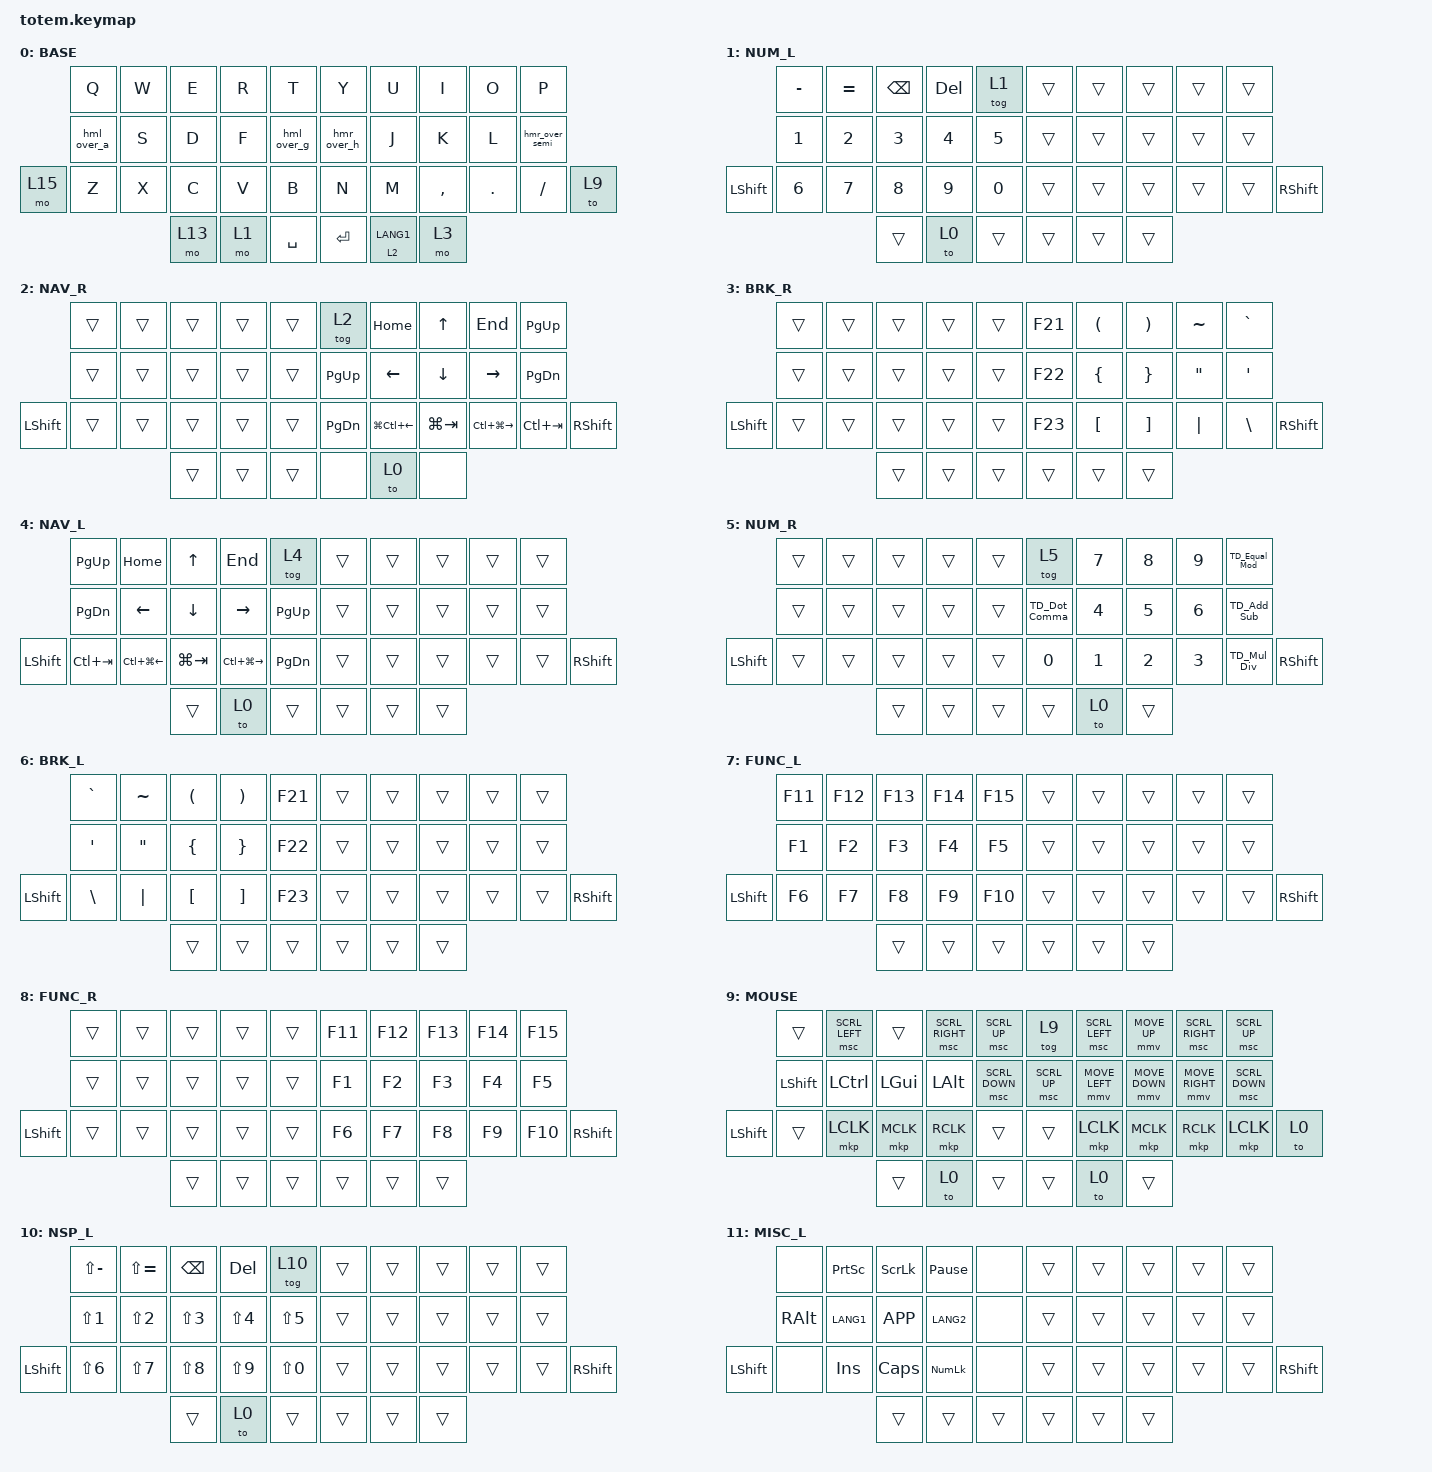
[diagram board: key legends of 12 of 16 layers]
//
//                                                        ▀▀▀▀▀     ▀▀▀▀▀          ▀▀█▀▀
//                                                        ▄▀▀▀▄  ▄  ▄▀▀▀▄  ▄  ▄▀▀▀▄  █  ▄▀▀▀▄
//                                                        █   █  █  █   █  █  █   █  █  █   █
//                                                         ▀▀▀   █   ▀▀▀   █   ▀▀▀   ▀   ▀▀▀
//                                                               █      ▄▄▄█▄▄▄    █   █  
//                                                               ▀      █  █  █     █▄█
//                                                             ▀▀▀▀▀    █  █  █      ▀
//                                                                      ▀  ▀  ▀
//
// ▄▄▄▄▄▄▄▄▄▄▄▄▄▄▄▄▄▄▄▄▄▄▄▄▄▄▄▄▄▄▄▄▄▄▄▄▄▄▄▄▄▄▄▄▄▄▄▄▄▄▄▄▄▄▄▄▄▄▄▄▄▄▄▄▄▄▄▄▄▄▄▄▄▄▄▄▄▄▄▄▄▄▄▄▄▄▄▄▄▄▄▄▄▄▄▄▄▄▄▄▄▄▄▄▄▄▄▄▄▄▄▄▄▄▄▄▄▄▄▄▄▄▄▄▄▄▄▄▄▄▄▄▄▄▄▄▄▄▄▄▄▄▄▄▄▄▄▄▄

#include <behaviors.dtsi>
#include <dt-bindings/zmk/bt.h>
#include <dt-bindings/zmk/keys.h>
#include <dt-bindings/zmk/outputs.h>
#include <dt-bindings/zmk/pointing.h>

&mt {
    quick-tap-ms = <175>;
    flavor = "balanced";
};

&lt {
    tapping-term-ms = <180>;
    flavor = "hold-preferred";
    hold-while-undecided;
};

&tog { toggle-mode = "on"; };

/ {
    combos {
        compatible = "zmk,combos";

        CAPS_L {
            bindings = <&kp CAPS>;
            key-positions = <23 33>;
            timeout-ms = <30>;
            layers = <0>;
        };

        TAB_L {
            bindings = <&kp TAB>;
            key-positions = <14 34>;
            timeout-ms = <30>;
            layers = <0>;
        };

        ENTER_L {
            bindings = <&kp ENTER>;
            key-positions = <34 4>;
            timeout-ms = <30>;
            layers = <0>;
        };

        ESC_L {
            bindings = <&kp ESC>;
            key-positions = <33 1>;
            timeout-ms = <30>;
            layers = <0>;
        };

        VOL_UP_L {
            bindings = <&kp C_VOL_UP>;
            key-positions = <33 4>;
            timeout-ms = <30>;
            require-prior-idle-ms = <200>;
            layers = <0>;
        };

        VOL_DN_L {
            bindings = <&kp C_VOL_DN>;
            key-positions = <33 14>;
            timeout-ms = <30>;
            require-prior-idle-ms = <200>;
            layers = <0>;
        };

        LCTRL_L {
            bindings = <&kp LCTRL>;
            key-positions = <11 12>;
            timeout-ms = <30>;
            require-prior-idle-ms = <70>;
            slow-release;
            layers = <0>;
        };

        LGUI_L {
            bindings = <&kp LGUI>;
            key-positions = <12 13>;
            timeout-ms = <30>;
            require-prior-idle-ms = <70>;
            slow-release;
            layers = <0>;
        };

        LALT_L {
            bindings = <&kp LALT>;
            key-positions = <13 14>;
            timeout-ms = <30>;
            require-prior-idle-ms = <70>;
            slow-release;
            layers = <0>;
        };

        MO_FUNC_L {
            bindings = <&mo 7>;
            key-positions = <33 13>;
            timeout-ms = <30>;
            slow-release;
            layers = <0 2 3 5 8 12>;
        };

        MO_FUNC_R {
            bindings = <&mo 8>;
            key-positions = <36 16>;
            timeout-ms = <30>;
            slow-release;
            layers = <0 1 4 6 7 10 11>;
        };

        MO_NAV_L {
            bindings = <&mo 4>;
            key-positions = <33 12>;
            timeout-ms = <30>;
            slow-release;
            layers = <0 2 3 5 8 12>;
        };

        MO_NUM_R {
            bindings = <&mo 5>;
            key-positions = <17 36>;
            timeout-ms = <30>;
            slow-release;
            layers = <0 1 4 6 7 10 11>;
        };

        MO_MISC_L {
            bindings = <&mo 11>;
            key-positions = <11 33>;
            timeout-ms = <30>;
            slow-release;
            layers = <0 2 3 5 8 12>;
        };

        MO_MISC_R {
            bindings = <&mo 12>;
            key-positions = <36 18>;
            timeout-ms = <30>;
            slow-release;
            layers = <0 1 4 6 7 10 11>;
        };

        MO_BRK_L {
            bindings = <&mo 6>;
            key-positions = <33 25>;
            timeout-ms = <30>;
            slow-release;
            layers = <0 2 3 5 8 12>;
        };

        MO_NUMSP_L {
            bindings = <&mo 10>;
            key-positions = <33 24>;
            timeout-ms = <30>;
            slow-release;
            layers = <0 2 3 5 8 12>;
        };

        MO_MOUSE {
            bindings = <&mo 9>;
            key-positions = <36 27>;
            timeout-ms = <30>;
            require-prior-idle-ms = <200>;
            slow-release;
            layers = <0>;
        };

        TO_BASE_L {
            bindings = <&to 0>;
            key-positions = <32 33 34>;
            timeout-ms = <30>;
        };

        MO_SETTING {
            bindings = <&mo 14>;
            key-positions = <11 4 2 33>;
            timeout-ms = <30>;
            slow-release;
        };

        bootload {
            bindings = <&bootloader>;
            key-positions = <4 25>;
            layers = <14>;
        };

        sysreset {
            bindings = <&sys_reset>;
            key-positions = <11 3>;
            layers = <14>;
        };

        LCTRL_SHFT_L {
            bindings = <&kp LC(LSHIFT)>;
            key-positions = <10 11>;
            timeout-ms = <30>;
            require-prior-idle-ms = <70>;
            slow-release;
            layers = <0>;
        };

        LALT_SHFT_L {
            bindings = <&kp LA(LSHIFT)>;
            key-positions = <10 13>;
            timeout-ms = <30>;
            require-prior-idle-ms = <70>;
            slow-release;
            layers = <0>;
        };

        LCTRL_ALT_L {
            bindings = <&kp LC(LALT)>;
            key-positions = <11 14>;
            timeout-ms = <30>;
            require-prior-idle-ms = <70>;
            slow-release;
            layers = <0>;
        };

        LGUI_SHFT_L {
            bindings = <&kp LS(LGUI)>;
            key-positions = <10 12>;
            timeout-ms = <30>;
            require-prior-idle-ms = <70>;
            slow-release;
            layers = <0>;
        };

        LGUI_CTRL_L {
            bindings = <&kp LC(LGUI)>;
            key-positions = <11 13>;
            timeout-ms = <30>;
            require-prior-idle-ms = <70>;
            slow-release;
            layers = <0>;
        };

        TO_BASE_R {
            bindings = <&to 0>;
            key-positions = <35 36 37>;
            timeout-ms = <30>;
        };

        B_R {
            bindings = <&kp B>;
            key-positions = <26 27>;
            timeout-ms = <30>;
            layers = <0>;
        };

        SHFT_P_R {
            bindings = <&kp LS(P)>;
            key-positions = <18 6>;
            timeout-ms = <30>;
            layers = <0>;
        };

        P_R {
            bindings = <&kp P>;
            key-positions = <18 16>;
            timeout-ms = <30>;
            layers = <0>;
        };

        LGUI_ALT_L {
            bindings = <&kp LA(LGUI)>;
            key-positions = <12 14>;
            timeout-ms = <30>;
            require-prior-idle-ms = <70>;
            slow-release;
            layers = <0>;
        };

        LCAG_L {
            bindings = <&kp LC(LA(LGUI))>;
            key-positions = <11 12 13>;
            timeout-ms = <30>;
            require-prior-idle-ms = <70>;
            slow-release;
            layers = <0>;
        };

        O_R {
            bindings = <&kp O>;
            key-positions = <18 17>;
            timeout-ms = <30>;
            layers = <0>;
        };

        SHFT_O_R {
            bindings = <&kp RS(O)>;
            key-positions = <18 7>;
            timeout-ms = <30>;
            layers = <0>;
        };

        MENU_R {
            bindings = <&kp K_CONTEXT_MENU>;
            key-positions = <36 28>;
            timeout-ms = <30>;
            layers = <0>;
        };

        LANG2_R {
            bindings = <&kp LANG2>;
            key-positions = <36 29>;
            timeout-ms = <30>;
            layers = <0>;
        };

        RALT_L {
            bindings = <&kp LANG1>;
            key-positions = <22 23>;
            timeout-ms = <30>;
            layers = <0>;
        };
    };

    behaviors {
        TD_Dot_Comma: TD_Dot_Comma {
            compatible = "zmk,behavior-tap-dance";
            label = "TD_DOT_COMMA";
            #binding-cells = <0>;
            bindings = <&kp DOT>, <&kp COMMA>;

            tapping-term-ms = <180>;
        };

        TD_Add_Sub: TD_Add_Sub {
            compatible = "zmk,behavior-tap-dance";
            label = "TD_ADD_SUB";
            #binding-cells = <0>;
            bindings = <&kp PLUS>, <&kp MINUS>;

            tapping-term-ms = <180>;
        };

        TD_Mul_Div: TD_Mul_Div {
            compatible = "zmk,behavior-tap-dance";
            label = "TD_MUL_DIV";
            #binding-cells = <0>;
            bindings = <&kp ASTERISK>, <&kp SLASH>;

            tapping-term-ms = <180>;
        };

        hml: hml {
            compatible = "zmk,behavior-hold-tap";
            label = "HML";
            bindings = <&kp>, <&kp>;

            #binding-cells = <2>;
            tapping-term-ms = <165>;
            flavor = "balanced";
        };

        hmr: hmr {
            compatible = "zmk,behavior-hold-tap";
            label = "HMR";
            bindings = <&kp>, <&kp>;

            #binding-cells = <2>;
            tapping-term-ms = <165>;
            flavor = "balanced";
        };

        lt_spc: lt_spc {
            compatible = "zmk,behavior-hold-tap";
            label = "LT_SPC";
            bindings = <&mo>, <&kp>;

            #binding-cells = <2>;
            tapping-term-ms = <250>;
            quick-tap-ms = <200>;
            require-prior-idle-ms = <250>;
            flavor = "tap-preferred";
        };

        TD_Equal_Mod: TD_Equal_Mod {
            compatible = "zmk,behavior-tap-dance";
            label = "TD_EQUAL_MOD";
            #binding-cells = <0>;
            bindings = <&kp EQUAL>, <&kp PERCENT>;

            tapping-term-ms = <180>;
        };

        hml_over_a: hml_over_a {
            compatible = "zmk,behavior-mod-morph";
            label = "HML_OVER_A";
            bindings = <&hml LSHFT A>, <&kp A>;

            #binding-cells = <0>;
            mods = <(MOD_LSFT|MOD_RSFT)>;
            keep-mods = <(MOD_LSFT|MOD_RSFT)>;
        };

        hml_over_g: hml_over_g {
            compatible = "zmk,behavior-mod-morph";
            label = "HML_OVER_G";
            bindings = <&hml_l LSHFT G>, <&kp G>;

            #binding-cells = <0>;
            mods = <(MOD_LSFT|MOD_RSFT)>;
            keep-mods = <(MOD_LSFT|MOD_RSFT)>;
        };

        hmr_over_semi: hmr_over_semi {
            compatible = "zmk,behavior-mod-morph";
            label = "HMR_OVER_SEMI";
            bindings = <&hmr RSHFT SEMICOLON>, <&kp SEMICOLON>;

            #binding-cells = <0>;
            mods = <(MOD_LSFT|MOD_RSFT)>;
            keep-mods = <(MOD_LSFT|MOD_RSFT)>;
        };

        hmr_over_h: hmr_over_h {
            compatible = "zmk,behavior-mod-morph";
            label = "HMR_OVER_H";
            bindings = <&hmr_r RSHFT H>, <&kp H>;

            #binding-cells = <0>;
            mods = <(MOD_LSFT|MOD_RSFT)>;
            keep-mods = <(MOD_LSFT|MOD_RSFT)>;
        };

        overrider: overrider {
            compatible = "zmk,behavior-hold-tap";
            label = "OVERRIDER";
            bindings = <&kp>, <&none>;

            #binding-cells = <2>;
            retro-tap;
            tapping-term-ms = <100>;
        };

        lt_r: lt_r {
            compatible = "zmk,behavior-hold-tap";
            label = "LT_R";
            bindings = <&mo>, <&kp>;

            #binding-cells = <2>;
            tapping-term-ms = <180>;
            hold-while-undecided;
            hold-trigger-key-positions = <16 26 15 5 7 6 17 27 28 29 18 8 9 19 30 31 37 36 35>;
        };

        hml_l: hml_l {
            compatible = "zmk,behavior-hold-tap";
            label = "HML_L";
            bindings = <&kp>, <&kp>;

            #binding-cells = <2>;
            tapping-term-ms = <165>;
            flavor = "balanced";
            hold-trigger-key-positions = <10>;
        };

        hmr_r: hmr_r {
            compatible = "zmk,behavior-hold-tap";
            label = "HMR_R";
            bindings = <&kp>, <&kp>;

            #binding-cells = <2>;
            tapping-term-ms = <165>;
            flavor = "balanced";
            hold-trigger-key-positions = <19>;
        };
    };

    keymap {
        compatible = "zmk,keymap";

        BASE_LR {
            bindings = <
        &kp Q        &kp W  &kp E   &kp R  &kp T          &kp Y        &kp U          &kp I      &kp O    &kp P
        &hml_over_a  &kp S  &kp D   &kp F  &hml_over_g    &hmr_over_h  &kp J          &kp K      &kp L    &hmr_over_semi
&mo 15  &kp Z        &kp X  &kp C   &kp V  &kp B          &kp N        &kp M          &kp COMMA  &kp DOT  &kp FSLH        &to 9
                            &mo 13  &mo 1  &kp SPACE      &kp ENTER    &lt_r 2 LANG1  &mo 3
            >;

            label = "BASE";
        };

        NUM_L {
            bindings = <
            &kp MINUS     &kp EQUAL     &kp BACKSPACE  &kp DELETE    &tog 1          &trans  &trans  &trans  &trans  &trans
            &kp NUMBER_1  &kp NUMBER_2  &kp NUMBER_3   &kp NUMBER_4  &kp N5          &trans  &trans  &trans  &trans  &trans
&kp LSHIFT  &kp NUMBER_6  &kp NUMBER_7  &kp NUMBER_8   &kp NUMBER_9  &kp NUMBER_0    &trans  &trans  &trans  &trans  &trans  &kp RSHFT
                                        &trans         &to 0         &trans          &trans  &trans  &trans
            >;

            label = "NUM_L";
        };

        NAV_R {
            bindings = <
           &trans  &trans  &trans  &trans  &trans    &tog 2     &kp HOME          &kp UP       &kp END            &kp PG_UP
           &trans  &trans  &trans  &trans  &trans    &kp PG_UP  &kp LEFT          &kp DOWN     &kp RIGHT          &kp PG_DN
&kp LSHFT  &trans  &trans  &trans  &trans  &trans    &kp PG_DN  &kp LG(LC(LEFT))  &kp LG(TAB)  &kp LC(LG(RIGHT))  &kp LC(TAB)  &kp RSHFT
                           &trans  &trans  &trans    &none      &to 0             &none
            >;

            label = "NAV_R";
        };

        BRK_R {
            bindings = <
           &trans  &trans  &trans  &trans  &trans    &kp F21  &kp LEFT_PARENTHESIS  &kp RIGHT_PARENTHESIS  &kp TILDE          &kp GRAVE
           &trans  &trans  &trans  &trans  &trans    &kp F22  &kp LEFT_BRACE        &kp RIGHT_BRACE        &kp DOUBLE_QUOTES  &kp SQT
&kp LSHFT  &trans  &trans  &trans  &trans  &trans    &kp F23  &kp LEFT_BRACKET      &kp RIGHT_BRACKET      &kp PIPE           &kp BACKSLASH  &kp RSHFT
                           &trans  &trans  &trans    &trans   &trans                &trans
            >;

            label = "BRK_R";
        };

        NAV_L {
            bindings = <
           &kp PG_UP    &kp HOME          &kp UP       &kp END            &tog 4       &trans  &trans  &trans  &trans  &trans
           &kp PG_DN    &kp LEFT          &kp DOWN     &kp RIGHT          &kp PG_UP    &trans  &trans  &trans  &trans  &trans
&kp LSHFT  &kp LC(TAB)  &kp LC(LG(LEFT))  &kp LG(TAB)  &kp LC(LG(RIGHT))  &kp PG_DN    &trans  &trans  &trans  &trans  &trans  &kp RSHFT
                                          &trans       &to 0              &trans       &trans  &trans  &trans
            >;

            label = "NAV_L";
        };

        NUM_R {
            bindings = <
           &trans  &trans  &trans  &trans  &trans    &tog 5         &kp NUMBER_7  &kp NUMBER_8  &kp NUMBER_9  &TD_Equal_Mod
           &trans  &trans  &trans  &trans  &trans    &TD_Dot_Comma  &kp NUMBER_4  &kp NUMBER_5  &kp NUMBER_6  &TD_Add_Sub
&kp LSHFT  &trans  &trans  &trans  &trans  &trans    &kp NUMBER_0   &kp NUMBER_1  &kp NUMBER_2  &kp NUMBER_3  &TD_Mul_Div    &kp RSHFT
                           &trans  &trans  &trans    &trans         &to 0         &trans
            >;

            label = "NUM_R";
        };

        BRK_L {
            bindings = <
           &kp GRAVE      &kp TILDE          &kp LEFT_PARENTHESIS  &kp RIGHT_PARENTHESIS  &kp F21    &trans  &trans  &trans  &trans  &trans
           &kp SQT        &kp DOUBLE_QUOTES  &kp LEFT_BRACE        &kp RIGHT_BRACE        &kp F22    &trans  &trans  &trans  &trans  &trans
&kp LSHFT  &kp BACKSLASH  &kp PIPE           &kp LEFT_BRACKET      &kp RIGHT_BRACKET      &kp F23    &trans  &trans  &trans  &trans  &trans  &kp RSHFT
                                             &trans                &trans                 &trans     &trans  &trans  &trans
            >;

            label = "BRK_L";
        };

        FUNC_L {
            bindings = <
           &kp F11  &kp F12  &kp F13  &kp F14  &kp F15    &trans  &trans  &trans  &trans  &trans
           &kp F1   &kp F2   &kp F3   &kp F4   &kp F5     &trans  &trans  &trans  &trans  &trans
&kp LSHFT  &kp F6   &kp F7   &kp F8   &kp F9   &kp F10    &trans  &trans  &trans  &trans  &trans  &kp RSHFT
                             &trans   &trans   &trans     &trans  &trans  &trans
            >;

            label = "FUNC_L";
        };

        FUNC_R {
            bindings = <
           &trans  &trans  &trans  &trans  &trans    &kp F11  &kp F12  &kp F13  &kp F14  &kp F15
           &trans  &trans  &trans  &trans  &trans    &kp F1   &kp F2   &kp F3   &kp F4   &kp F5
&kp LSHFT  &trans  &trans  &trans  &trans  &trans    &kp F6   &kp F7   &kp F8   &kp F9   &kp F10  &kp RSHFT
                           &trans  &trans  &trans    &trans   &trans   &trans
            >;

            label = "FUNC_R";
        };

        MOUSE_LR {
            bindings = <
           &trans          &msc SCRL_LEFT  &trans        &msc SCRL_RIGHT  &msc SCRL_UP      &tog 9        &msc SCRL_LEFT  &mmv MOVE_UP    &msc SCRL_RIGHT  &msc SCRL_UP
           &kp LEFT_SHIFT  &kp LCTRL       &kp LEFT_GUI  &kp LALT         &msc SCRL_DOWN    &msc SCRL_UP  &mmv MOVE_LEFT  &mmv MOVE_DOWN  &mmv MOVE_RIGHT  &msc SCRL_DOWN
&kp LSHFT  &trans          &mkp LCLK       &mkp MCLK     &mkp RCLK        &trans            &trans        &mkp LCLK       &mkp MCLK       &mkp RCLK        &mkp LCLK       &to 0
                                           &trans        &to 0            &trans            &trans        &to 0           &trans
            >;

            label = "MOUSE";
        };

        NUMSP_L {
            bindings = <
           &kp LS(MINUS)     &kp LS(EQUAL)     &kp BACKSPACE     &kp DEL           &tog 10             &trans  &trans  &trans  &trans  &trans
           &kp LS(NUMBER_1)  &kp LS(NUMBER_2)  &kp LS(NUMBER_3)  &kp LS(NUMBER_4)  &kp LS(NUMBER_5)    &trans  &trans  &trans  &trans  &trans
&kp LSHFT  &kp LS(NUMBER_6)  &kp LS(NUMBER_7)  &kp LS(NUMBER_8)  &kp LS(NUMBER_9)  &kp LS(NUMBER_0)    &trans  &trans  &trans  &trans  &trans  &kp RSHFT
                                               &trans            &to 0             &trans              &trans  &trans  &trans
            >;

            label = "NSP_L";
        };

        MISC_L {
            bindings = <
           &none     &kp PSCRN  &kp SCROLLLOCK  &kp PAUSE_BREAK  &none     &trans  &trans  &trans  &trans  &trans
           &kp RALT  &kp LANG1  &kp K_APP       &kp LANG2        &none     &trans  &trans  &trans  &trans  &trans
&kp LSHFT  &none     &kp INS    &kp CAPS        &kp KP_NUM       &none     &trans  &trans  &trans  &trans  &trans  &kp RSHFT
                                &trans          &trans           &trans    &trans  &trans  &trans
            >;

            label = "MISC_L";
        };

        MISC_R {
            bindings = <
           &trans  &trans  &trans  &trans  &trans    &none   &kp PAUSE_BREAK  &kp SLCK   &kp PSCRN  &none
           &trans  &trans  &trans  &trans  &trans    &none   &kp LANGUAGE_2   &kp K_APP  &kp LANG1  &kp RALT
&kp LSHFT  &trans  &trans  &trans  &trans  &trans    &none   &kp KP_NUM       &kp CAPS   &kp INS    &none     &kp RSHFT
                           &trans  &trans  &trans    &trans  &trans           &trans
            >;

            label = "MISC_R";
        };

        MIRROR_L {
            bindings = <
           &kp P           &kp O       &kp I      &kp U   &kp Y          &trans  &trans  &trans  &trans  &trans
           &hmr_over_semi  &kp L       &kp K      &kp J   &hmr_over_h    &trans  &trans  &trans  &trans  &trans
&kp LSHFT  &kp SLASH       &kp PERIOD  &kp COMMA  &kp M   &kp N          &trans  &trans  &trans  &trans  &trans  &kp RSHFT
                                       &trans     &trans  &trans         &trans  &trans  &trans
            >;

            label = "MIRROR";
        };

        SETTING_LR {
            bindings = <
       &bt BT_DISC 0  &bt BT_DISC 1  &bt BT_DISC 2  &bt BT_DISC 3  &bt BT_DISC 4     &none      &none   &none   &none  &none
       &bt BT_SEL 0   &bt BT_SEL 1   &bt BT_SEL 2   &bt BT_SEL 3   &bt BT_SEL 4      &none      &none   &none   &none  &none
&none  &bt BT_CLR     &bt BT_PRV     &bt BT_NXT     &out OUT_TOG   &bt BT_CLR_ALL    &none      &none   &none   &none  &none  &none
                                     &trans         &trans         &kp SPACE         &kp ENTER  &trans  &trans
            >;

            label = "SET";
        };

        CUSTOM_L {
            bindings = <
       &kp F24  &kp F21  &kp F18  &kp F15  &kp C_VOL_UP    &none   &none     &none     &none      &none
       &kp F23  &kp F20  &kp F17  &kp F14  &kp C_VOL_DN    &none   &kp LALT  &kp LGUI  &kp LCTRL  &kp RSHFT
&none  &kp F22  &kp F19  &kp F16  &kp F13  &kp K_MUTE      &none   &none     &none     &none      &none      &none
                         &trans   &trans   &trans          &trans  &trans    &trans
            >;

            label = "CUST_L";
        };
    };

    conditional_layers { compatible = "zmk,conditional-layers"; };
};
